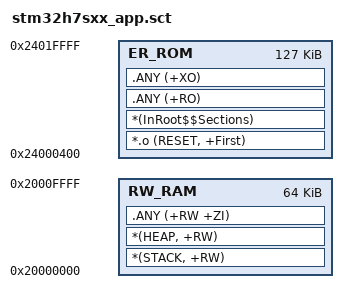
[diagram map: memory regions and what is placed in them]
#! armclang --target=arm-arm-none-eabi -march=armv7-m -E -xc

; *************************************************************
; *** Scatter-Loading Description File generated by uVision ***
; *************************************************************

#define CODE_OFFSET 0x24000000    /* Firmware execution area offset from STiROT_Config.xml */
#define CODE_SIZE 0x20000      /* Firmware area size from STiROT_Config.xml */
#define IMAGE_HEADER_SIZE 0x400     /* mcuboot header size */

#define CODE_START (CODE_OFFSET + IMAGE_HEADER_SIZE)
#define APP_CODE_SIZE CODE_SIZE - IMAGE_HEADER_SIZE

LOAD_FLASH CODE_START CODE_SIZE  {    ; load region size_region
  ER_ROM CODE_START APP_CODE_SIZE  {  ; load address = execution address
   *.o (RESET, +First)
   *(InRoot$$Sections)
   .ANY (+RO)
   .ANY (+XO)
  }

  RW_RAM 0x20000000  0x00010000  {
   *(STACK, +RW)
   *(HEAP, +RW)
   .ANY (+RW +ZI)
  }
}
